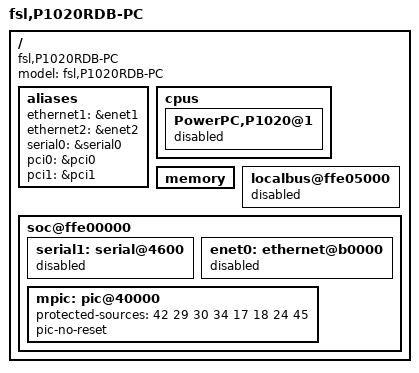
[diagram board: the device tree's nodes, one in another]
/include/ "p1020rdb-pc_32b.dts"
/ {
	model = "fsl,P1020RDB-PC";
	compatible = "fsl,P1020RDB-PC";
	aliases {
		ethernet1 = &enet1;
		ethernet2 = &enet2;
		serial0 = &serial0;
		pci0 = &pci0;
		pci1 = &pci1;
	};
	cpus {
		PowerPC,P1020@1 {
			status = "disabled";
		};
	};
	memory {
		device_type = "memory";
	};
	localbus@ffe05000 {
		status = "disabled";
	};
	soc@ffe00000 {
		serial1: serial@4600 {
			status = "disabled";
		};
		enet0: ethernet@b0000 {
			status = "disabled";
		};
		mpic: pic@40000 {
			protected-sources = <
			42 29 30 34	 
			17 18 24 45	 
			>;
			pic-no-reset;
		};
	};
};
